# NANO103AE_v1 register map
File version: 1.0
NANO103AE_v1 SVD file
Registers are 32-bit, read-write, reset 0x0 unless marked. A register's access mark holds for its fields unless they carry their own. Offsets are from the block's base; lines under a group give offsets from that group; [hi:lo] are bit positions; {n}, {i} and the like mark numbered series; 'fields as' and 'values as' point back to an identical list; <NAME> marks a mode.

## Memory map
0x40004000 WDT size 0xC — WDT Register Map
0x40004100 WWDT size 0x14 — WWDT Register Map
0x40008000 RTC blocks up to offset 0x110 — RTC Register Map
0x40010000 TMR01 blocks up to offset 0x218 — TMR Register Map
0x40020000 I2C0 blocks up to offset 0x48 — I2C Register Map
0x40030000 SPI0 blocks up to offset 0x54 — SPI Register Map
0x40040000 PWM0 blocks up to offset 0x1000 — PWM0 Register Map
0x40050000 UART0 blocks up to offset 0x48 — UART Register Map
0x400D0000 SPI2 blocks up to offset 0x54 — SPI Register Map
0x400E0000 ADC blocks up to offset 0x78 — ADC Register Map
0x40110000 TMR23 blocks up to offset 0x124 — TMR Register Map
0x40120000 I2C1 blocks up to offset 0x48 — I2C Register Map
0x40130000 SPI1 blocks up to offset 0x54 — SPI Register Map
0x40150000 UART1 blocks up to offset 0x48 — UART Register Map
0x40190000 SC0 blocks up to offset 0x44 — SC Register Map
0x401B0000 SC1 blocks up to offset 0x44 — SC Register Map
0x401D0000 ACMP0 size 0xC — ACMP0 Register Map
0x401E0000 SPI3 blocks up to offset 0x54 — SPI Register Map
0x401F0000 DSRC blocks up to offset 0x21C — DSRC Register Map
0x50000000 SYS blocks up to offset 0x124 — SYS Register Map
0x50000200 CLK blocks up to offset 0x4C — CLK Register Map
0x50000300 INT size 0x88 — SCS Register Map
0x50004000 GPIO blocks up to offset 0x360 — GPIO Register Map
0x50008100 PDMA_CH1 blocks up to offset 0x2C — PDMA Register Map
0x50008200 PDMA_CH2 blocks up to offset 0x2C — PDMA Register Map
0x50008300 PDMA_CH3 blocks up to offset 0x2C — PDMA Register Map
0x50008400 PDMA_CH4 blocks up to offset 0x2C — PDMA Register Map
0x50008E00 CRC blocks up to offset 0x8C — PDMA Register Map
0x50008F00 PDMA_GCR size 0x10 — PDMA Register Map
0x5000C000 FMC blocks up to offset 0x6C — FMC Register Map
0xE000E000 SCS blocks up to offset 0xD24 — SCS Register Map

## INT — SCS Register Map
Base 0x50000300
{0x0+4i} IRQ{i}_SRC ro reset not defined (i=0..31) — MCU IRQ{i} (BOD_INT) interrupt source identify
  [3:0] INT_SRC — Interrupt Source. Define the interrupt sources for interrupt event.
0x80 NMI_SEL — NMI Source Interrupt Select Control Register
  [4:0] NMI_SEL — NMI Interrupt to Cortex-M0 Can Be Selected From One of the Interrupt[31:0]. The NMI_SEL bit[4:0] is used to select the NMI interrupt source
0x84 MCU_IRQ — MCU Interrupt Request Source Register
  [31:0] MCU_IRQ — MCU IRQ Source Bits. The MCU_IRQ collects all the interrupts from the peripherals and generates the synchronous interrupt to MCU Cortex-M0. There are two modes to generate interrupt to Cortex-M0, the normal mode. The MCU_IRQ collects all interrupts from each peripheral and synchronizes them and then interrupts the Cortex-M0. When the MCU_IRQ[n] is "0", setting MCU_IRQ[n] "1" will generate an interrupt to Cortex-M0 NVIC[n]. When the MCU_IRQ[n] is "1" (means an interrupt is asserted), setting the MCU_bit[n] will clear the interrupt. Set MCU_IRQ[n] "0": no any effect

## PDMA_GCR — PDMA Register Map
Base 0x50008F00
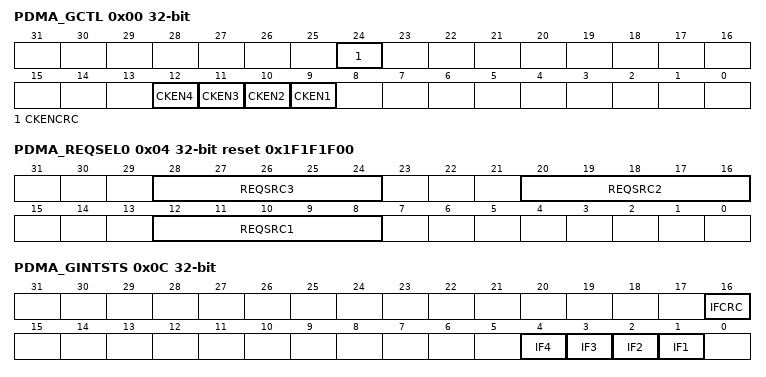
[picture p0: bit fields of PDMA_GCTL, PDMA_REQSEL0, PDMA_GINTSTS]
0x00 PDMA_GCTL — PDMA Global Control Register
  [24] CKENCRC — CRC Controller Clock Enable Bit
    0=CRC channel clock Disabled; 1=CRC channel clock Enabled
  [n+8] CKEN{n} (n=1..4) — PDMA Controller Channel {n} Clock Enable Bit
    0=PDMA channel {n} clock Disabled; 1=PDMA channel {n} clock Enabled
0x04 PDMA_REQSEL0 reset 0x1F1F1F00 — PDMA Request Source Select Register 0
  [28:24] REQSRC3 — Channel 3 Request Source Selection. This filed defines which peripheral is connected to PDMA channel 3. User can configure the peripheral setting by REQSRC3. Note: The channel configuration is the same as REQSRC1 field. Please refer to the explanation of REQSRC1.
  [20:16] REQSRC2 — Channel 2 Request Source Selection. This filed defines which peripheral is connected to PDMA channel 2. User can configure the peripheral setting by REQSRC2. Note: The channel configuration is the same as REQSRC1 field. Please refer to the explanation of REQSRC1.
  [12:8] REQSRC1 — Channel 1 Request Source Selection. This filed defines which peripheral is connected to PDMA channel 1. User can configure the peripheral by setting REQSRC1
    0=Connect to SPI0_TX; 1=Connect to SPI1_TX; 2=Connect to UART0_TX; 3=Connect to UART1_TX; 5=Connect to SPI3_TX; 8=Connect to SPI2_TX; {v}=Connect to TMR{v-9} (v=9..12); 16=Connect to SPI0_RX; 17=Connect to SPI1_RX; 18=Connect to UART0_RX; 19=Connect to UART1_RX; 21=Connect to SPI3_RX; 22=Connect to ADC; 24=Connect to SPI2_RX
0x08 PDMA_REQSEL1 reset 0x1F — PDMA Request Source Select Register 1
  [4:0] REQSRC4 — Channel 4 Request Source Selection. This filed defines which peripheral is connected to PDMA channel 4. User can configure the peripheral setting by REQSRC4. Note: The channel configuration is the same as REQSRC1 field. Please refer to the explanation of REQSRC1.
0x0C PDMA_GINTSTS ro — PDMA Global Interrupt Status Register
  [16] IFCRC — CRC Controller Interrupt Status Flag (Read Only). This bit indicates the interrupt status of CRC controller
  [4] IF4 — PDMA Channel 4 Interrupt Status Flag (Read Only). This bit indicates the interrupt status of PDMA channel 4.
  [3] IF3 — PDMA Channel 3 Interrupt Status (Read Only). This bit indicates the interrupt status of PDMA channel 3.
  [2] IF2 — PDMA Channel 2 Interrupt Status Flag of (Read Only). This bit indicates the interrupt status of PDMA channel 2.
  [1] IF1 — PDMA Channel 1 Interrupt Status (Read Only). This bit indicates the interrupt status of PDMA channel 1.
